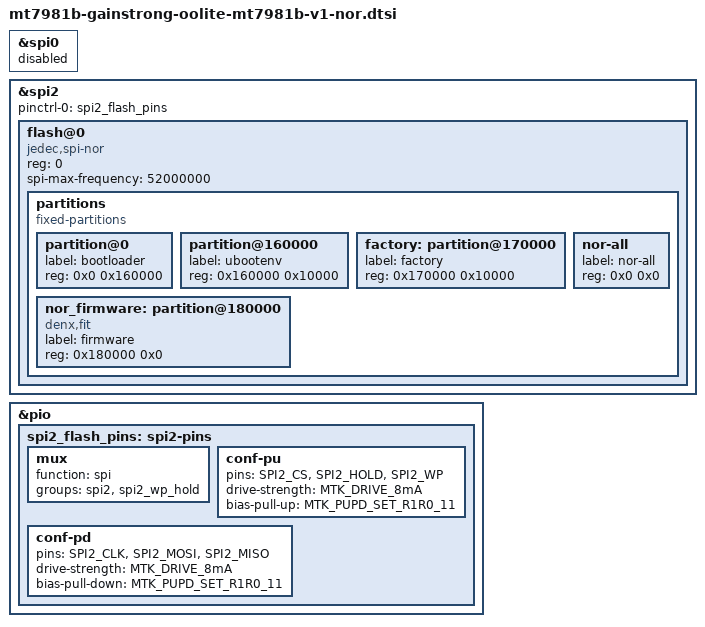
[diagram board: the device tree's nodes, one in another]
#include <dt-bindings/pinctrl/mt65xx.h>

&spi0 {
	status = "disabled";
};

&spi2 {
	pinctrl-names = "default";
	pinctrl-0 = <&spi2_flash_pins>;
	#address-cells = <1>;
	#size-cells = <0>;
	status = "okay";

	flash@0 {
		compatible = "jedec,spi-nor";
		reg = <0>;
		spi-max-frequency = <52000000>;

		partitions {
			compatible = "fixed-partitions";
			#address-cells = <1>;
			#size-cells = <1>;

			partition@0 {
				label = "bootloader";
				reg = <0x0 0x160000>;
			};

			partition@160000 {
				label = "ubootenv";
				reg = <0x160000 0x10000>;
			};

			factory: partition@170000 {
				label = "factory";
				reg = <0x170000 0x10000>;
			};

			nor_firmware: partition@180000 {
				compatible = "denx,fit";
				label = "firmware";
				reg = <0x180000 0x0>;
			};

			/* Raw access to the whole SPI-NOR for maintenance operations. */
			nor-all {
				label = "nor-all";
				reg = <0x0 0x0>;
			};
		};
	};
};
&pio {
	spi2_flash_pins: spi2-pins {
		mux {
			function = "spi";
			groups = "spi2", "spi2_wp_hold";
		};

		conf-pu {
			pins = "SPI2_CS", "SPI2_HOLD", "SPI2_WP";
			drive-strength = <MTK_DRIVE_8mA>;
			bias-pull-up = <MTK_PUPD_SET_R1R0_11>;
		};

		conf-pd {
			pins = "SPI2_CLK", "SPI2_MOSI", "SPI2_MISO";
			drive-strength = <MTK_DRIVE_8mA>;
			bias-pull-down = <MTK_PUPD_SET_R1R0_11>;
		};
	};
};
